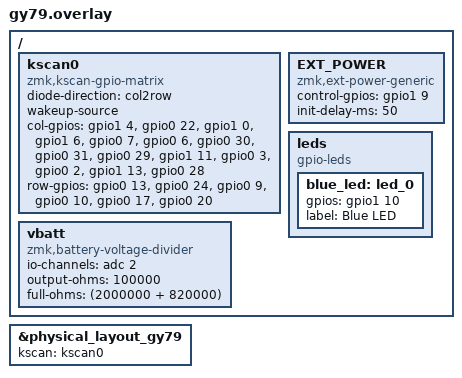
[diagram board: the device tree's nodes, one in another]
#include "gy79.dtsi"

/ {
    kscan0: kscan0 {
        compatible = "zmk,kscan-gpio-matrix";
        diode-direction = "col2row";
        wakeup-source;

        col-gpios
            = <&pro_micro 8 GPIO_ACTIVE_HIGH>
            , <&pro_micro 4 GPIO_ACTIVE_HIGH>
            , <&pro_micro 6 GPIO_ACTIVE_HIGH>
            , <&pro_micro 9 GPIO_ACTIVE_HIGH>
            , <&pro_micro 0 GPIO_ACTIVE_HIGH>
            , <&pro_micro 1 GPIO_ACTIVE_HIGH>
            , <&pro_micro 7 GPIO_ACTIVE_HIGH>
            , <&pro_micro 21 GPIO_ACTIVE_HIGH>
            , <&pro_micro 20 GPIO_ACTIVE_HIGH>
            , <&pro_micro 14 GPIO_ACTIVE_HIGH>
            , <&pro_micro 19 GPIO_ACTIVE_HIGH>
            , <&pro_micro 18 GPIO_ACTIVE_HIGH>
            , <&pro_micro 15 GPIO_ACTIVE_HIGH>
            , <&pro_micro 16 GPIO_ACTIVE_HIGH>
            ;

        row-gpios
            = <&pro_micro 10 (GPIO_ACTIVE_HIGH | GPIO_PULL_DOWN)>
            , <&pro_micro 5 (GPIO_ACTIVE_HIGH | GPIO_PULL_DOWN)>
            , <&gpio1 1 (GPIO_ACTIVE_HIGH | GPIO_PULL_DOWN)>
            , <&gpio1 2 (GPIO_ACTIVE_HIGH | GPIO_PULL_DOWN)>
            , <&pro_micro 2 (GPIO_ACTIVE_HIGH | GPIO_PULL_DOWN)>
            , <&pro_micro 3 (GPIO_ACTIVE_HIGH | GPIO_PULL_DOWN)>
            ;

        col-gpios
			= <&gpio1 4 GPIO_ACTIVE_HIGH>
			, <&gpio0 22 GPIO_ACTIVE_HIGH>
			, <&gpio1 0 GPIO_ACTIVE_HIGH>
			, <&gpio1 6 GPIO_ACTIVE_HIGH>
			, <&gpio0 7 GPIO_ACTIVE_HIGH>     
			, <&gpio0 6 GPIO_ACTIVE_HIGH>
			, <&gpio0 30 GPIO_ACTIVE_HIGH>
			, <&gpio0 31 GPIO_ACTIVE_HIGH>
			, <&gpio0 29 GPIO_ACTIVE_HIGH>
			, <&gpio1 11 GPIO_ACTIVE_HIGH>
			, <&gpio0 3 GPIO_ACTIVE_HIGH>
			, <&gpio0 2 GPIO_ACTIVE_HIGH>
			, <&gpio1 13 GPIO_ACTIVE_HIGH>
			, <&gpio0 28 GPIO_ACTIVE_HIGH>
			;

		row-gpios
			= <&gpio0 13 (GPIO_ACTIVE_HIGH | GPIO_PULL_DOWN)>
			, <&gpio0 24 (GPIO_ACTIVE_HIGH | GPIO_PULL_DOWN)>
			, <&gpio0  9 (GPIO_ACTIVE_HIGH | GPIO_PULL_DOWN)>
			, <&gpio0 10 (GPIO_ACTIVE_HIGH | GPIO_PULL_DOWN)>
			, <&gpio0 17 (GPIO_ACTIVE_HIGH | GPIO_PULL_DOWN)>
			, <&gpio0 20 (GPIO_ACTIVE_HIGH | GPIO_PULL_DOWN)>
			;
    };
    EXT_POWER {
		compatible = "zmk,ext-power-generic";
		control-gpios = <&gpio1 9 GPIO_ACTIVE_HIGH>;
		init-delay-ms = <50>;
	};
    leds {
		compatible = "gpio-leds";
		blue_led: led_0 {
			gpios = <&gpio1 10 GPIO_ACTIVE_HIGH>;
			label = "Blue LED";
		};
	};

	vbatt: vbatt {
		compatible = "zmk,battery-voltage-divider";
		io-channels = <&adc 2>;
		output-ohms = <100000>;
		full-ohms = <(2000000 + 820000)>;
	};

};
/delete-node/ &i2c0;
/delete-node/ &spi1;
/delete-node/ &uart0;
&physical_layout_gy79 {
    kscan = <&kscan0>;
};

